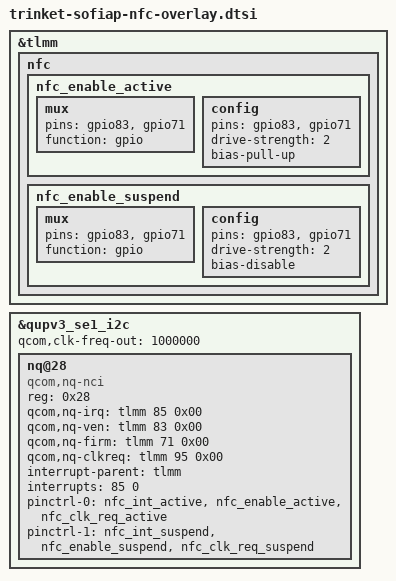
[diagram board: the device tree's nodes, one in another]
&tlmm {
    nfc {
            nfc_enable_active: nfc_enable_active {
            /* active state */
            mux {
                /* 83: Enable 71: Firmware */
                pins = "gpio83", "gpio71";
                function = "gpio";
            };

            config {
                pins = "gpio83", "gpio71";
                drive-strength = <2>; /* 2 MA */
                bias-pull-up;
            };
        };

        nfc_enable_suspend: nfc_enable_suspend {
            /* sleep state */
            mux {
                /* 83: Enable 71: Firmware */
                pins = "gpio83", "gpio71";
                function = "gpio";
            };

            config {
                pins = "gpio83", "gpio71";
                drive-strength = <2>; /* 2 MA */
                bias-disable;
            };
        };
    };
};

&qupv3_se1_i2c {
	status = "ok";
	qcom,clk-freq-out = <1000000>;
	nq@28 {
		compatible = "qcom,nq-nci";
		reg = <0x28>;
		qcom,nq-irq = <&tlmm 85 0x00>;
		qcom,nq-ven = <&tlmm 83 0x00>;
		qcom,nq-firm = <&tlmm 71 0x00>;
		qcom,nq-clkreq = <&tlmm 95 0x00>;
		interrupt-parent = <&tlmm>;
		interrupts = <85 0>;
		interrupt-names = "nfc_irq";
		pinctrl-names = "nfc_active", "nfc_suspend";
		pinctrl-0 = <&nfc_int_active &nfc_enable_active
				&nfc_clk_req_active>;
		pinctrl-1 = <&nfc_int_suspend &nfc_enable_suspend
				&nfc_clk_req_suspend>;
	};
};
